# STM32MP23_CM33 register map
File version: 1.2
CPU: CM33 r0p1, little endian, MPU, FPU, vendor SysTick, 8 interrupt priority bits
Registers are 32-bit, read-write, reset 0x0 unless marked. A register's access mark holds for its fields unless they carry their own. Offsets are from the block's base; [hi:lo] are bit positions; lines under a group give offsets from that group; {n}, {i} and the like mark numbered series.

## DDRPERFM — DDRPERFM register block
Base 0x48041000
Same registers: DDRPERFM_S 0x58041000
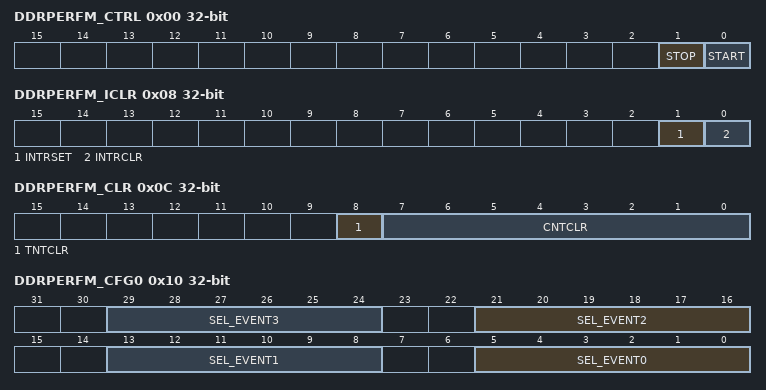
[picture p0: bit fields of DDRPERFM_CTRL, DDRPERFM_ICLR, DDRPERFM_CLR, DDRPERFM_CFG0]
0x00 DDRPERFM_CTRL — DDRPERFM control register
  [1] STOP — Writing 1 stops all counters. Writing 0 has no effect. Writing 1 when counters are stopped has not effect.
  [0] START — Writing 1 starts all counters. All internal counters and status bits are cleared before events are monitored. Writing 0 has no effect. Writing 1 when counters are running has not effect.
0x04 DDRPERFM_IMSK — DDRPERFM interrupt mask register
  [0] INTRMSK
    0=No effect; 1=DDRPERFM interruption signal masked
0x08 DDRPERFM_ICLR — DDRPERFM interrupt clear register
  [1] INTRSET
    0=No effect; 1=Set the interruption signal when asserted
  [0] INTRCLR — Note: The counters must be cleared first (to remove the interruption condition) before the interruption is cleared.
    0=No effect; 1=Clear the interruption signal when asserted
0x0C DDRPERFM_CLR — DDRPERFM counter clear register
  [8] TNTCLR — Note: Setting this bit is ignored if BUSY = 1 in DDRPERFM_STATUS.
    0=No effect; 1=Clear free running counter and associated status bits (timeout and overflow indicators)
  [7:0] CNTCLR — Note: Setting this bit is ignored if BUSY = 1 in DDRPERFM_STATUS.
    0=No effect; 1=Clear corresponding counters and associated status bits (timeout and overflow indicators)
0x10 DDRPERFM_CFG0 — DDRPERFM configuration register 0
  [8n+5:8n] SEL_EVENT{n} (n=0..3) — Selection of the performance logging signal to be monitored by the event counter {n}
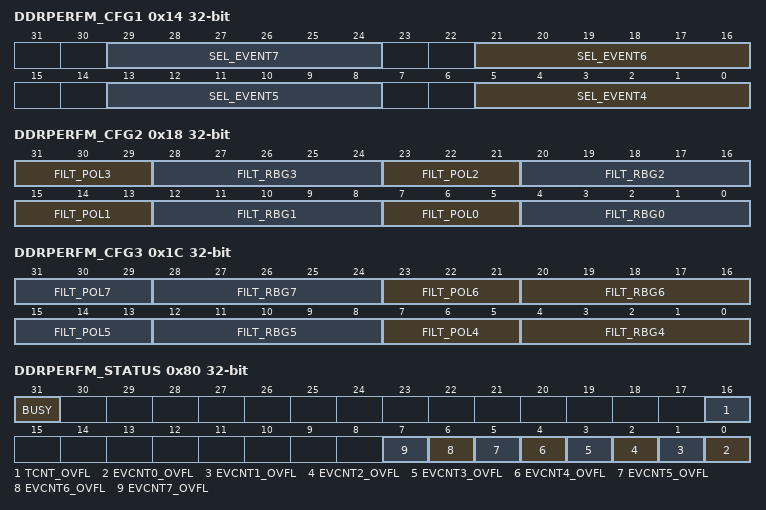
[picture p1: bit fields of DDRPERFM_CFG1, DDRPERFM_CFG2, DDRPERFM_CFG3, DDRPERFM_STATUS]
0x14 DDRPERFM_CFG1 — DDRPERFM configuration register 1
  [8n-27:8n-32] SEL_EVENT{n} (n=4..7) — Selection of the performance logging signal to be monitored by the event counter {n}
0x18 DDRPERFM_CFG2 — DDRPERFM configuration register 2
  [31:29] FILT_POL3 — Selection of the performance logging signal to be monitored by the event counter 3 Filtering policy for the event counter 3 (refer to Table72).
  [28:24] FILT_RBG3 — Configuration of the rank/bank/bank group filtering for the event counter 3 based on FILT_POL3 value Bit 4: Define the rank value when rank filtering is activated. Value 0 means that only commands applied on Rank0 are counted. Value 1 means that only commands applied on rank1 are counted. Bits 3:0: Define drank group/bank address/ used for filtering When filtering is activated: - For DDR4, the FILT_RBGx[3:2] bits correspond to bank group, and FILT_RBGx[1:0] correspond to bank address. - For LPDDR3/4, the DDR3 bits FILT_RBGx[2:0] bits correspond to bank address, and FILT_RBG3 is unused.
  [23:21] FILT_POL2 — Filtering policy for the event counter 2. (refer to Table72)
  [20:16] FILT_RBG2 — Configuration of the rank/bank/bank group filtering for the event counter 2 based on FILT_POL2 value
  [15:13] FILT_POL1 — Filtering policy for the event counter 1 (refer to Table72)
  [12:8] FILT_RBG1 — Configuration of the rank/bank/bank group filtering for the event counter 1 based on FILT_POL1 value
  [7:5] FILT_POL0 — Filtering policy for the event counter 0 (refer to Table72)
  [4:0] FILT_RBG0 — Configuration of the rank/bank/bank group filtering for the event counter 0 based on FILT_POL0 value
0x1C DDRPERFM_CFG3 — DDRPERFM configuration register 3
  [8n-25:8n-27] FILT_POL{n} (n=4..7) — Filtering policy for the event counter {n} (refer to Table72)
  [8n-28:8n-32] FILT_RBG{n} (n=4..7) — Configuration of the rank/bank/bank group filtering for the event counter {n} based on FILT_POL{n} value
0x20 DDRPERFM_CFG4 reset 0xFFFFFFFF — DDRPERFM configuration register 4
  [31:0] TIME_OUT — Timeout value for the time counter When this value is reached, the DDRPERFM automatically stops: All counters are frozen. The status bit TCNT_TIMOUT is asserted. The (maskable) interrupt signal is asserted.
0x24 DDRPERFM_CFG5 — DDRPERFM event counter enable register
  [7:0] EVCNT_EN — Event counter enable When bit i is set, the corresponding counter is enabled. Note: Enable must be written when counters are not running.
0x28 DDRPERFM_DRAMINF — DDRPERFM DRAM information register
  [1:0] DRAM_TYPE — DRAM information used for DFI decoding
    0=LPDDR4; 1=LPDDR3; 2=DDR4; 3=DDR3
{0x40+4i} DDRPERFM_EVCNT{i} ro (i=0..7) — DDRPERFM event counter {i} register
  [31:0] EVCNT{i} — Counter value for event {i}
0x60 DDRPERFM_TCNT ro — DDRPERFM time counter register
  [31:0] TCNT — Time counter value Must only be read when the PERFM is stopped.
0x80 DDRPERFM_STATUS ro
  [31] BUSY — Real-time busy indicator This bit is asserted as long as counters are running, and deasserted when a stop condition occurs (software controlled stop command or counter overflow).
  [16] TCNT_OVFL — When read to 1, the DDRPERFM is stopped due to time counter reaching the timeout value.
  [n] EVCNT{n}_OVFL (n=0..7) — When read to 1, the DDRPERFM is stopped due to event counter {n} overflow.
